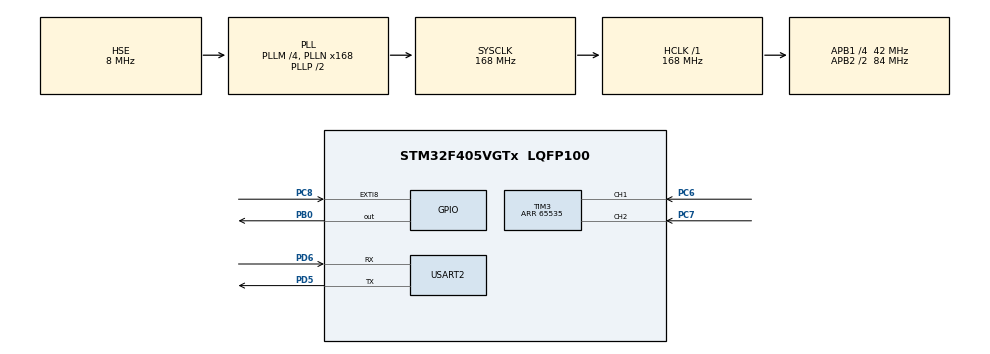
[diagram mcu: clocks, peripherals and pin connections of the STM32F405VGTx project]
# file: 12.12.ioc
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Mcu.Family=STM32F4
Mcu.Name=STM32F405VGTx
Mcu.Package=LQFP100
NVIC.PriorityGroup=NVIC_PRIORITYGROUP_4
NVIC.TIM3_IRQn=true\:0\:0\:false\:false\:true\:true\:true
PA13.Mode=Serial_Wire
PA13.Signal=SYS_JTMS-SWDIO
PA14.Mode=Serial_Wire
PA14.Signal=SYS_JTCK-SWCLK
PB0.PinState=GPIO_PIN_SET
PB0.Signal=GPIO_Output
PC6.Signal=S_TIM3_CH1
PC7.Signal=S_TIM3_CH2
PC8.Signal=GPXTI8
PD5.Mode=Asynchronous
PD5.Signal=USART2_TX
PD6.Mode=Asynchronous
PD6.Signal=USART2_RX
PH0-OSC_IN.Mode=HSE-External-Oscillator
PH0-OSC_IN.Signal=RCC_OSC_IN
PH1-OSC_OUT.Mode=HSE-External-Oscillator
PH1-OSC_OUT.Signal=RCC_OSC_OUT
ProjectManager.HeapSize=0x200
ProjectManager.StackSize=0x400
ProjectManager.TargetToolchain=Makefile
RCC.48MHZClocksFreq_Value=84000000
RCC.AHBFreq_Value=168000000
RCC.APB1CLKDivider=RCC_HCLK_DIV4
RCC.APB1Freq_Value=42000000
RCC.APB1TimFreq_Value=84000000
RCC.APB2CLKDivider=RCC_HCLK_DIV2
RCC.APB2Freq_Value=84000000
RCC.APB2TimFreq_Value=168000000
RCC.CortexFreq_Value=168000000
RCC.HCLKFreq_Value=168000000
RCC.HSE_VALUE=8000000
RCC.HSI_VALUE=16000000
RCC.LSE_VALUE=32768
RCC.PLLM=4
RCC.PLLN=168
RCC.PLLSourceVirtual=RCC_PLLSOURCE_HSE
RCC.SYSCLKFreq_VALUE=168000000
RCC.SYSCLKSource=RCC_SYSCLKSOURCE_PLLCLK
RCC.VCOOutputFreq_Value=336000000
SH.S_TIM3_CH1.0=TIM3_CH1,Encoder_Interface
SH.S_TIM3_CH2.0=TIM3_CH2,Encoder_Interface
TIM3.EncoderMode=TIM_ENCODERMODE_TI12
TIM3.Period=65535
USART2.VirtualMode=VM_ASYNC
board=custom

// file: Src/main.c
/* USER CODE BEGIN Header */
/**
  ******************************************************************************
  * @file           : main.c
  * @brief          : Main program body
  ******************************************************************************
  * @attention
  *
  * <h2><center>&copy; Copyright (c) 2019 STMicroelectronics.
  * All rights reserved.</center></h2>
  *
  * This software component is licensed by ST under BSD 3-Clause license,
  * the "License"; You may not use this file except in compliance with the
  * License. You may obtain a copy of the License at:
  *                        opensource.org/licenses/BSD-3-Clause
  *
  ******************************************************************************
  */
/* USER CODE END Header */

#include "main.h"
#include "stdint.h"

TIM_HandleTypeDef htim3;

UART_HandleTypeDef huart2;

void SystemClock_Config(void);
static void MX_GPIO_Init(void);
static void MX_TIM3_Init(void);
static void MX_USART2_UART_Init(void);

int main(void)
{
  /* USER CODE BEGIN 1 */
uint32_t wang=0;
  /* USER CODE END 1 */

  /* MCU Configuration--------------------------------------------------------*/

  /* Reset of all peripherals, Initializes the Flash interface and the Systick. */
  HAL_Init();

  /* Configure the system clock */
  SystemClock_Config();

  /* Initialize all configured peripherals */
  MX_GPIO_Init();
  MX_TIM3_Init();
  MX_USART2_UART_Init();

  /* Infinite loop */
  while (1)
  {

   HAL_GPIO_WritePin(GPIOB, GPIO_PIN_0, GPIO_PIN_RESET);

  wang= (uint32_t)__HAL_TIM_GET_COUNTER(&htim3);

  }
}

void SystemClock_Config(void)
{
  RCC_OscInitTypeDef RCC_OscInitStruct = {0};
  RCC_ClkInitTypeDef RCC_ClkInitStruct = {0};

  /** Configure the main internal regulator output voltage
  */
  __HAL_RCC_PWR_CLK_ENABLE();
  __HAL_PWR_VOLTAGESCALING_CONFIG(PWR_REGULATOR_VOLTAGE_SCALE1);
  /** Initializes the CPU, AHB and APB busses clocks
  */
  RCC_OscInitStruct.OscillatorType = RCC_OSCILLATORTYPE_HSE;
  RCC_OscInitStruct.HSEState = RCC_HSE_ON;
  RCC_OscInitStruct.PLL.PLLState = RCC_PLL_ON;
  RCC_OscInitStruct.PLL.PLLSource = RCC_PLLSOURCE_HSE;
  RCC_OscInitStruct.PLL.PLLM = 4;
  RCC_OscInitStruct.PLL.PLLN = 168;
  RCC_OscInitStruct.PLL.PLLP = RCC_PLLP_DIV2;
  RCC_OscInitStruct.PLL.PLLQ = 4;
  if (HAL_RCC_OscConfig(&RCC_OscInitStruct) != HAL_OK)
  {
    Error_Handler();
  }
  /** Initializes the CPU, AHB and APB busses clocks
  */
  RCC_ClkInitStruct.ClockType = RCC_CLOCKTYPE_HCLK|RCC_CLOCKTYPE_SYSCLK
                              |RCC_CLOCKTYPE_PCLK1|RCC_CLOCKTYPE_PCLK2;
  RCC_ClkInitStruct.SYSCLKSource = RCC_SYSCLKSOURCE_PLLCLK;
  RCC_ClkInitStruct.AHBCLKDivider = RCC_SYSCLK_DIV1;
  RCC_ClkInitStruct.APB1CLKDivider = RCC_HCLK_DIV4;
  RCC_ClkInitStruct.APB2CLKDivider = RCC_HCLK_DIV2;

  if (HAL_RCC_ClockConfig(&RCC_ClkInitStruct, FLASH_LATENCY_5) != HAL_OK)
  {
    Error_Handler();
  }
}

static void MX_TIM3_Init(void)
{

  TIM_Encoder_InitTypeDef sConfig = {0};
  TIM_MasterConfigTypeDef sMasterConfig = {0};

  htim3.Instance = TIM3;
  htim3.Init.Prescaler = 0;
  htim3.Init.CounterMode = TIM_COUNTERMODE_UP;
  htim3.Init.Period = 65535;
  htim3.Init.ClockDivision = TIM_CLOCKDIVISION_DIV1;
  htim3.Init.AutoReloadPreload = TIM_AUTORELOAD_PRELOAD_DISABLE;
  sConfig.EncoderMode = TIM_ENCODERMODE_TI12;
  sConfig.IC1Polarity = TIM_ICPOLARITY_RISING;
  sConfig.IC1Selection = TIM_ICSELECTION_DIRECTTI;
  sConfig.IC1Prescaler = TIM_ICPSC_DIV1;
  sConfig.IC1Filter = 0;
  sConfig.IC2Polarity = TIM_ICPOLARITY_RISING;
  sConfig.IC2Selection = TIM_ICSELECTION_DIRECTTI;
  sConfig.IC2Prescaler = TIM_ICPSC_DIV1;
  sConfig.IC2Filter = 0;
  if (HAL_TIM_Encoder_Init(&htim3, &sConfig) != HAL_OK)
  {
    Error_Handler();
  }
  sMasterConfig.MasterOutputTrigger = TIM_TRGO_RESET;
  sMasterConfig.MasterSlaveMode = TIM_MASTERSLAVEMODE_DISABLE;
  if (HAL_TIMEx_MasterConfigSynchronization(&htim3, &sMasterConfig) != HAL_OK)
  {
    Error_Handler();
  }

}

static void MX_USART2_UART_Init(void)
{

  huart2.Instance = USART2;
  huart2.Init.BaudRate = 115200;
  huart2.Init.WordLength = UART_WORDLENGTH_8B;
  huart2.Init.StopBits = UART_STOPBITS_1;
  huart2.Init.Parity = UART_PARITY_NONE;
  huart2.Init.Mode = UART_MODE_TX_RX;
  huart2.Init.HwFlowCtl = UART_HWCONTROL_NONE;
  huart2.Init.OverSampling = UART_OVERSAMPLING_16;
  if (HAL_UART_Init(&huart2) != HAL_OK)
  {
    Error_Handler();
  }

}

static void MX_GPIO_Init(void)
{
  GPIO_InitTypeDef GPIO_InitStruct = {0};

  /* GPIO Ports Clock Enable */
  __HAL_RCC_GPIOH_CLK_ENABLE();
  __HAL_RCC_GPIOB_CLK_ENABLE();
  __HAL_RCC_GPIOC_CLK_ENABLE();
  __HAL_RCC_GPIOA_CLK_ENABLE();
  __HAL_RCC_GPIOD_CLK_ENABLE();

  /*Configure GPIO pin Output Level */
  HAL_GPIO_WritePin(GPIOB, GPIO_PIN_0, GPIO_PIN_SET);

  /*Configure GPIO pin : PB0 */
  GPIO_InitStruct.Pin = GPIO_PIN_0;
  GPIO_InitStruct.Mode = GPIO_MODE_OUTPUT_PP;
  GPIO_InitStruct.Pull = GPIO_NOPULL;
  GPIO_InitStruct.Speed = GPIO_SPEED_FREQ_LOW;
  HAL_GPIO_Init(GPIOB, &GPIO_InitStruct);

  /*Configure GPIO pin : PC8 */
  GPIO_InitStruct.Pin = GPIO_PIN_8;
  GPIO_InitStruct.Mode = GPIO_MODE_IT_RISING;
  GPIO_InitStruct.Pull = GPIO_NOPULL;
  HAL_GPIO_Init(GPIOC, &GPIO_InitStruct);

}

void Error_Handler(void)
{
}

/************************ (C) COPYRIGHT STMicroelectronics *****END OF FILE****/
